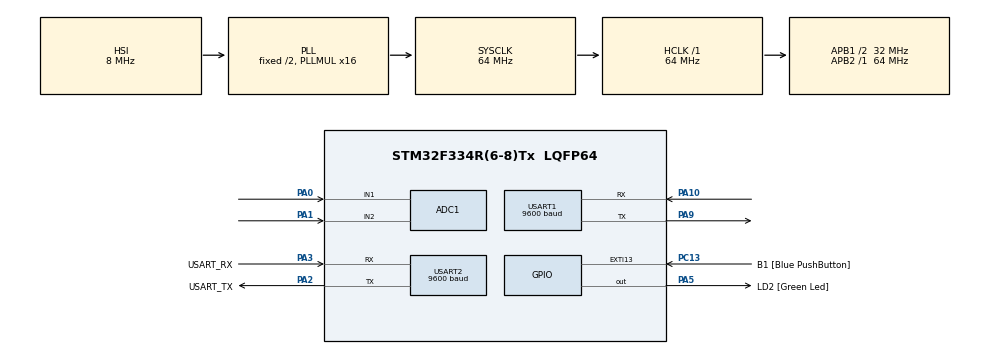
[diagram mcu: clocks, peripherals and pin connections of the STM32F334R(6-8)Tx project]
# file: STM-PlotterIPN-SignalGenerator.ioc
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ADC1.Channel-0\#ChannelRegularConversion=ADC_CHANNEL_1
ADC1.ContinuousConvMode=ENABLE
ADC1.NbrOfConversionFlag=1
ADC1.Offset-0\#ChannelRegularConversion=0
ADC1.OffsetNumber-0\#ChannelRegularConversion=ADC_OFFSET_NONE
ADC1.Rank-0\#ChannelRegularConversion=1
ADC1.SamplingTime-0\#ChannelRegularConversion=ADC_SAMPLETIME_1CYCLE_5
ADC1.SamplingTimeOPAMP-0\#ChannelRegularConversion=ADC_SAMPLETIME_61CYCLES_5
ADC1.SingleDiff-0\#ChannelRegularConversion=ADC_DIFFERENTIAL_ENDED
ADC1.SubFamily=STM32F334x8
ADC1.master=1
Mcu.Family=STM32F3
Mcu.Name=STM32F334R(6-8)Tx
Mcu.Package=LQFP64
NVIC.PriorityGroup=NVIC_PRIORITYGROUP_0
PA0.Mode=IN1-Differential
PA0.Signal=ADC1_IN1
PA1.Mode=IN1-Differential
PA1.Signal=ADC1_IN2
PA10.Mode=Asynchronous
PA10.Signal=USART1_RX
PA13.GPIO_Label=TMS
PA13.Mode=Serial_Wire
PA13.Signal=SYS_JTMS-SWDIO
PA14.GPIO_Label=TCK
PA14.Mode=Serial_Wire
PA14.Signal=SYS_JTCK-SWCLK
PA2.GPIO_Label=USART_TX
PA2.Mode=Asynchronous
PA2.Signal=USART2_TX
PA3.GPIO_Label=USART_RX
PA3.Mode=Asynchronous
PA3.Signal=USART2_RX
PA5.GPIO_Label=LD2 [Green Led]
PA5.Signal=GPIO_Output
PA9.Mode=Asynchronous
PA9.Signal=USART1_TX
PB3.GPIO_Label=SWO
PB3.Signal=SYS_JTDO-TRACESWO
PC13.GPIO_Label=B1 [Blue PushButton]
PC13.GPIO_ModeDefaultEXTI=GPIO_MODE_IT_FALLING
PC13.Signal=GPXTI13
PC14\ /\ OSC32_IN.Mode=LSE-External-Oscillator
PC14\ /\ OSC32_IN.Signal=RCC_OSC32_IN
PC15\ /\ OSC32_OUT.GPIO_Label=RCC_OSC32_OUT
PC15\ /\ OSC32_OUT.Mode=LSE-External-Oscillator
PC15\ /\ OSC32_OUT.Signal=RCC_OSC32_OUT
PF0\ /\ OSC_IN.Mode=HSE-External-Clock-Source
PF0\ /\ OSC_IN.Signal=RCC_OSC_IN
PF1\ /\ OSC_OUT.Signal=RCC_OSC_OUT
ProjectManager.HeapSize=0x200
ProjectManager.StackSize=0x400
ProjectManager.TargetToolchain=STM32CubeIDE
RCC.AHBFreq_Value=64000000
RCC.APB1CLKDivider=RCC_HCLK_DIV2
RCC.APB1Freq_Value=32000000
RCC.APB1TimFreq_Value=64000000
RCC.APB2Freq_Value=64000000
RCC.APB2TimFreq_Value=64000000
RCC.CortexFreq_Value=64000000
RCC.FLatency-AdvancedSettings=FLASH_LATENCY_2
RCC.HCLKFreq_Value=64000000
RCC.HSE_VALUE=8000000
RCC.HSI_VALUE=8000000
RCC.PLLMUL=RCC_PLL_MUL16
RCC.SYSCLKFreq_VALUE=64000000
RCC.SYSCLKSourceVirtual=RCC_SYSCLKSOURCE_PLLCLK
USART1.BaudRate=9600
USART1.VirtualMode-Asynchronous=VM_ASYNC
USART2.BaudRate=9600
USART2.VirtualMode-Asynchronous=VM_ASYNC
board=NUCLEO-F334R8

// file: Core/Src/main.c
/* USER CODE BEGIN Header */
/**
  ******************************************************************************
  * @file           : main.c
  * @brief          : Main program body
  ******************************************************************************
  * @attention
  *
  * Copyright (c) 2025 STMicroelectronics.
  * All rights reserved.
  *
  * This software is licensed under terms that can be found in the LICENSE file
  * in the root directory of this software component.
  * If no LICENSE file comes with this software, it is provided AS-IS.
  *
  ******************************************************************************
  */
/* USER CODE END Header */
#include "main.h"
#include <string.h>   // Para strlen()
#include <stdio.h>    // Para sprintf()
#include "math.h"
#include <stdbool.h>

/* USER CODE BEGIN Includes */

#ifndef M_PI
#define M_PI 3.14159265358979323846f
#endif

typedef enum {
  WAVE_SINE = 0,
  WAVE_SQUARE,
  WAVE_TRIANGLE,
  WAVE_SAWTOOTH
} WaveformType;

/* USER CODE END Includes */

ADC_HandleTypeDef hadc1;

UART_HandleTypeDef huart1;
UART_HandleTypeDef huart2;

/* Flag que define si se envían datos simulados (true)
   o valores capturados por el ADC (false).  Se modifica
   desde la interrupción del botón de usuario. */
volatile bool Simulacion = false;

void SystemClock_Config(void);
static void MX_GPIO_Init(void);
static void MX_USART2_UART_Init(void);
static void MX_ADC1_Init(void);
static void MX_USART1_UART_Init(void);

extern ADC_HandleTypeDef hadc1;
extern UART_HandleTypeDef huart2;

uint32_t adcValue1;
uint32_t adcValue2;
char buffer[64];

int main(void)
{

  /* MCU Configuration--------------------------------------------------------*/

  /* Reset of all peripherals, Initializes the Flash interface and the Systick. */
  HAL_Init();

  /* Configure the system clock */
  SystemClock_Config();

  /* Initialize all configured peripherals */
  MX_GPIO_Init();
  MX_USART2_UART_Init();
  MX_ADC1_Init();
  MX_USART1_UART_Init();
  int nSenalesSimulacion = 4; // Número de señales simuladas simultáneas (2-4)
  WaveformType signal_types[4] = {WAVE_SINE, WAVE_SQUARE, WAVE_TRIANGLE, WAVE_SAWTOOTH};
  float angles[4] = {0};

  HAL_Init();
  SystemClock_Config();
  MX_GPIO_Init();
  MX_ADC1_Init();
  MX_USART2_UART_Init();

  HAL_ADC_Start(&hadc1); // Inicia ADC

  /* Infinite loop */
  while (1)
  {

          if(Simulacion){
      uint16_t sim_values[4] = {0};
      for(int i = 0; i < nSenalesSimulacion && i < 4; i++){
        switch(signal_types[i]){
        case WAVE_SQUARE:
          sim_values[i] = (angles[i] < M_PI) ? 4095 : 0;
          break;
        case WAVE_TRIANGLE:
          {
            float t = fmodf(angles[i], 2.0f*M_PI)/(2.0f*M_PI);
            if(t < 0.5f)
              sim_values[i] = (uint16_t)(t*2.0f*4095);
            else
              sim_values[i] = (uint16_t)((1.0f - t)*2.0f*4095);
          }
          break;
        case WAVE_SAWTOOTH:
          {
            float t = fmodf(angles[i], 2.0f*M_PI)/(2.0f*M_PI);
            sim_values[i] = (uint16_t)(t*4095);
          }
          break;
        case WAVE_SINE:
        default:
          sim_values[i] = (uint16_t)((sin(angles[i]) + 1.0f) * 2047);
          break;
        }

        angles[i] += 0.025f;
        if(angles[i] >= 2.0f*M_PI) angles[i] -= 2.0f*M_PI;
      }

      char buffer[64];
      int len = 0;
      for(int i = 0; i < nSenalesSimulacion && i < 4; i++){
        len += sprintf(buffer + len, "%u", sim_values[i]);
        if(i < nSenalesSimulacion - 1)
          buffer[len++] = ',';
        else
          buffer[len++] = '\n';
      }
      HAL_UART_Transmit(&huart2, (uint8_t*)buffer, len, HAL_MAX_DELAY);
      HAL_Delay(10);
          }
	  else{
          // Datos de ADC de la tarjeta (dos canales)
          HAL_ADC_PollForConversion(&hadc1, HAL_MAX_DELAY);
          adcValue1 = HAL_ADC_GetValue(&hadc1);
          HAL_ADC_PollForConversion(&hadc1, HAL_MAX_DELAY);
          adcValue2 = HAL_ADC_GetValue(&hadc1);

          // Enviar por UART
          sprintf(buffer, "%lu,%lu\n", adcValue1, adcValue2);
          HAL_UART_Transmit(&huart2, (uint8_t*)buffer, strlen(buffer), HAL_MAX_DELAY);
          HAL_Delay(10); // Envía cada 200 ms

	  }

  }
}

void SystemClock_Config(void)
{
  RCC_OscInitTypeDef RCC_OscInitStruct = {0};
  RCC_ClkInitTypeDef RCC_ClkInitStruct = {0};
  RCC_PeriphCLKInitTypeDef PeriphClkInit = {0};

  /** Initializes the RCC Oscillators according to the specified parameters
  * in the RCC_OscInitTypeDef structure.
  */
  RCC_OscInitStruct.OscillatorType = RCC_OSCILLATORTYPE_HSI;
  RCC_OscInitStruct.HSIState = RCC_HSI_ON;
  RCC_OscInitStruct.HSICalibrationValue = RCC_HSICALIBRATION_DEFAULT;
  RCC_OscInitStruct.PLL.PLLState = RCC_PLL_ON;
  RCC_OscInitStruct.PLL.PLLSource = RCC_PLLSOURCE_HSI;
  RCC_OscInitStruct.PLL.PLLMUL = RCC_PLL_MUL16;
  if (HAL_RCC_OscConfig(&RCC_OscInitStruct) != HAL_OK)
  {
    Error_Handler();
  }

  /** Initializes the CPU, AHB and APB buses clocks
  */
  RCC_ClkInitStruct.ClockType = RCC_CLOCKTYPE_HCLK|RCC_CLOCKTYPE_SYSCLK
                              |RCC_CLOCKTYPE_PCLK1|RCC_CLOCKTYPE_PCLK2;
  RCC_ClkInitStruct.SYSCLKSource = RCC_SYSCLKSOURCE_PLLCLK;
  RCC_ClkInitStruct.AHBCLKDivider = RCC_SYSCLK_DIV1;
  RCC_ClkInitStruct.APB1CLKDivider = RCC_HCLK_DIV2;
  RCC_ClkInitStruct.APB2CLKDivider = RCC_HCLK_DIV1;

  if (HAL_RCC_ClockConfig(&RCC_ClkInitStruct, FLASH_LATENCY_2) != HAL_OK)
  {
    Error_Handler();
  }
  PeriphClkInit.PeriphClockSelection = RCC_PERIPHCLK_USART1|RCC_PERIPHCLK_ADC12;
  PeriphClkInit.Usart1ClockSelection = RCC_USART1CLKSOURCE_PCLK1;
  PeriphClkInit.Adc12ClockSelection = RCC_ADC12PLLCLK_DIV1;
  if (HAL_RCCEx_PeriphCLKConfig(&PeriphClkInit) != HAL_OK)
  {
    Error_Handler();
  }
}

static void MX_ADC1_Init(void)
{

  ADC_MultiModeTypeDef multimode = {0};
  ADC_ChannelConfTypeDef sConfig = {0};

  /** Common config
  */
  hadc1.Instance = ADC1;
  hadc1.Init.ClockPrescaler = ADC_CLOCK_ASYNC_DIV1;
  hadc1.Init.Resolution = ADC_RESOLUTION_12B;
  hadc1.Init.ScanConvMode = ADC_SCAN_ENABLE;
  hadc1.Init.ContinuousConvMode = ENABLE;
  hadc1.Init.DiscontinuousConvMode = DISABLE;
  hadc1.Init.ExternalTrigConvEdge = ADC_EXTERNALTRIGCONVEDGE_NONE;
  hadc1.Init.ExternalTrigConv = ADC_SOFTWARE_START;
  hadc1.Init.DataAlign = ADC_DATAALIGN_RIGHT;
  hadc1.Init.NbrOfConversion = 2;
  hadc1.Init.DMAContinuousRequests = DISABLE;
  hadc1.Init.EOCSelection = ADC_EOC_SINGLE_CONV;
  hadc1.Init.LowPowerAutoWait = DISABLE;
  hadc1.Init.Overrun = ADC_OVR_DATA_OVERWRITTEN;
  if (HAL_ADC_Init(&hadc1) != HAL_OK)
  {
    Error_Handler();
  }

  /** Configure the ADC multi-mode
  */
  multimode.Mode = ADC_MODE_INDEPENDENT;
  if (HAL_ADCEx_MultiModeConfigChannel(&hadc1, &multimode) != HAL_OK)
  {
    Error_Handler();
  }

  /** Configure Regular Channel
  */
  sConfig.Channel = ADC_CHANNEL_1;
  sConfig.Rank = ADC_REGULAR_RANK_1;
  sConfig.SingleDiff = ADC_DIFFERENTIAL_ENDED;
  sConfig.SamplingTime = ADC_SAMPLETIME_1CYCLE_5;
  sConfig.OffsetNumber = ADC_OFFSET_NONE;
  sConfig.Offset = 0;
  if (HAL_ADC_ConfigChannel(&hadc1, &sConfig) != HAL_OK)
  {
    Error_Handler();
  }

  /* Configure second regular channel */
  sConfig.Channel = ADC_CHANNEL_2;
  sConfig.Rank = ADC_REGULAR_RANK_2;
  if (HAL_ADC_ConfigChannel(&hadc1, &sConfig) != HAL_OK)
  {
    Error_Handler();
  }

}

static void MX_USART1_UART_Init(void)
{

  huart1.Instance = USART1;
  huart1.Init.BaudRate = 9600;
  huart1.Init.WordLength = UART_WORDLENGTH_8B;
  huart1.Init.StopBits = UART_STOPBITS_1;
  huart1.Init.Parity = UART_PARITY_NONE;
  huart1.Init.Mode = UART_MODE_TX_RX;
  huart1.Init.HwFlowCtl = UART_HWCONTROL_NONE;
  huart1.Init.OverSampling = UART_OVERSAMPLING_16;
  huart1.Init.OneBitSampling = UART_ONE_BIT_SAMPLE_DISABLE;
  huart1.AdvancedInit.AdvFeatureInit = UART_ADVFEATURE_NO_INIT;
  if (HAL_UART_Init(&huart1) != HAL_OK)
  {
    Error_Handler();
  }

}

static void MX_USART2_UART_Init(void)
{

  huart2.Instance = USART2;
  huart2.Init.BaudRate = 115200;
  huart2.Init.WordLength = UART_WORDLENGTH_8B;
  huart2.Init.StopBits = UART_STOPBITS_1;
  huart2.Init.Parity = UART_PARITY_NONE;
  huart2.Init.Mode = UART_MODE_TX_RX;
  huart2.Init.HwFlowCtl = UART_HWCONTROL_NONE;
  huart2.Init.OverSampling = UART_OVERSAMPLING_16;
  huart2.Init.OneBitSampling = UART_ONE_BIT_SAMPLE_DISABLE;
  huart2.AdvancedInit.AdvFeatureInit = UART_ADVFEATURE_NO_INIT;
  if (HAL_UART_Init(&huart2) != HAL_OK)
  {
    Error_Handler();
  }

}

static void MX_GPIO_Init(void)
{
  GPIO_InitTypeDef GPIO_InitStruct = {0};

  /* GPIO Ports Clock Enable */
  __HAL_RCC_GPIOC_CLK_ENABLE();
  __HAL_RCC_GPIOF_CLK_ENABLE();
  __HAL_RCC_GPIOA_CLK_ENABLE();
  __HAL_RCC_GPIOB_CLK_ENABLE();

  /*Configure GPIO pin Output Level */
  HAL_GPIO_WritePin(LD2_GPIO_Port, LD2_Pin, GPIO_PIN_RESET);

  /*Configure GPIO pin : B1_Pin */
  GPIO_InitStruct.Pin = B1_Pin;
  GPIO_InitStruct.Mode = GPIO_MODE_IT_FALLING;
  GPIO_InitStruct.Pull = GPIO_NOPULL;
  HAL_GPIO_Init(B1_GPIO_Port, &GPIO_InitStruct);

  /* Configurar y habilitar la interrupción del botón de usuario */
  HAL_NVIC_SetPriority(EXTI15_10_IRQn, 0, 0);
  HAL_NVIC_EnableIRQ(EXTI15_10_IRQn);

  /*Configure GPIO pin : LD2_Pin */
  GPIO_InitStruct.Pin = LD2_Pin;
  GPIO_InitStruct.Mode = GPIO_MODE_OUTPUT_PP;
  GPIO_InitStruct.Pull = GPIO_NOPULL;
  GPIO_InitStruct.Speed = GPIO_SPEED_FREQ_LOW;
  HAL_GPIO_Init(LD2_GPIO_Port, &GPIO_InitStruct);

}

/* USER CODE BEGIN 4 */

/**
  * @brief Callback de la interrupción generada por el botón de usuario
  *        Alterna la bandera 'Simulacion' para cambiar entre señal simulada
  *        y lectura real del ADC.
  */
void HAL_GPIO_EXTI_Callback(uint16_t GPIO_Pin)
{
  if (GPIO_Pin == B1_Pin)
  {
    Simulacion = !Simulacion;
  }
}

/* USER CODE END 4 */

void Error_Handler(void)
{
  __disable_irq();
  while (1)
  {
  }
}
